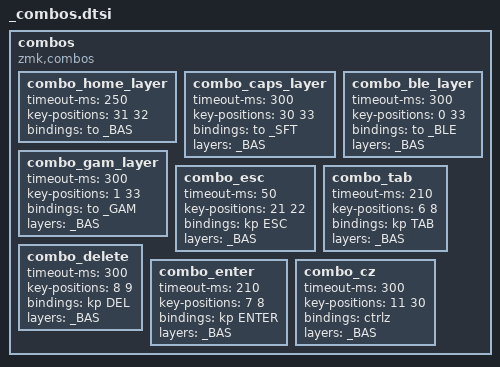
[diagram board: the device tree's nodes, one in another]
#ifndef HEADER
#define HEADER
#include "keymap.h"
#endif

    combos {
        compatible = "zmk,combos";

        combo_home_layer {
            timeout-ms = <250>;
            key-positions = <31 32>;
            bindings = <&to _BAS>;
        };

        combo_caps_layer {
            timeout-ms = <300>;
            key-positions = <30 33>;
            bindings = <&to _SFT>;
            layers = <_BAS>;
        };

        combo_ble_layer {
            timeout-ms = <300>;
            key-positions = <0 33>;
            bindings = <&to _BLE>;
            layers = <_BAS>;
        };

        combo_gam_layer {
            timeout-ms = <300>;
            key-positions = <1 33>;
            bindings = <&to _GAM>;
            layers = <_BAS>;
        };

        combo_esc {
            timeout-ms = <50>;
            key-positions = <21 22>;
            bindings = <&kp ESC>;
            layers = <_BAS>;
        };
        
        combo_tab {
            timeout-ms = <210>;
            key-positions = <6 8>;
            bindings = <&kp TAB>;
            layers = <_BAS>;
        };
               
        combo_delete {
            timeout-ms = <300>;
            key-positions = <8 9>;
            bindings = <&kp DEL>;
            layers = <_BAS>;
        };

        combo_enter {
            timeout-ms = <210>;
            key-positions = <7 8>;
            bindings = <&kp ENTER>;
            layers = <_BAS>;
        };

        combo_cz {
            timeout-ms = <300>;
            key-positions = <11 30>;
            bindings = <&ctrlz>;
            layers = <_BAS>;
        };

    };
